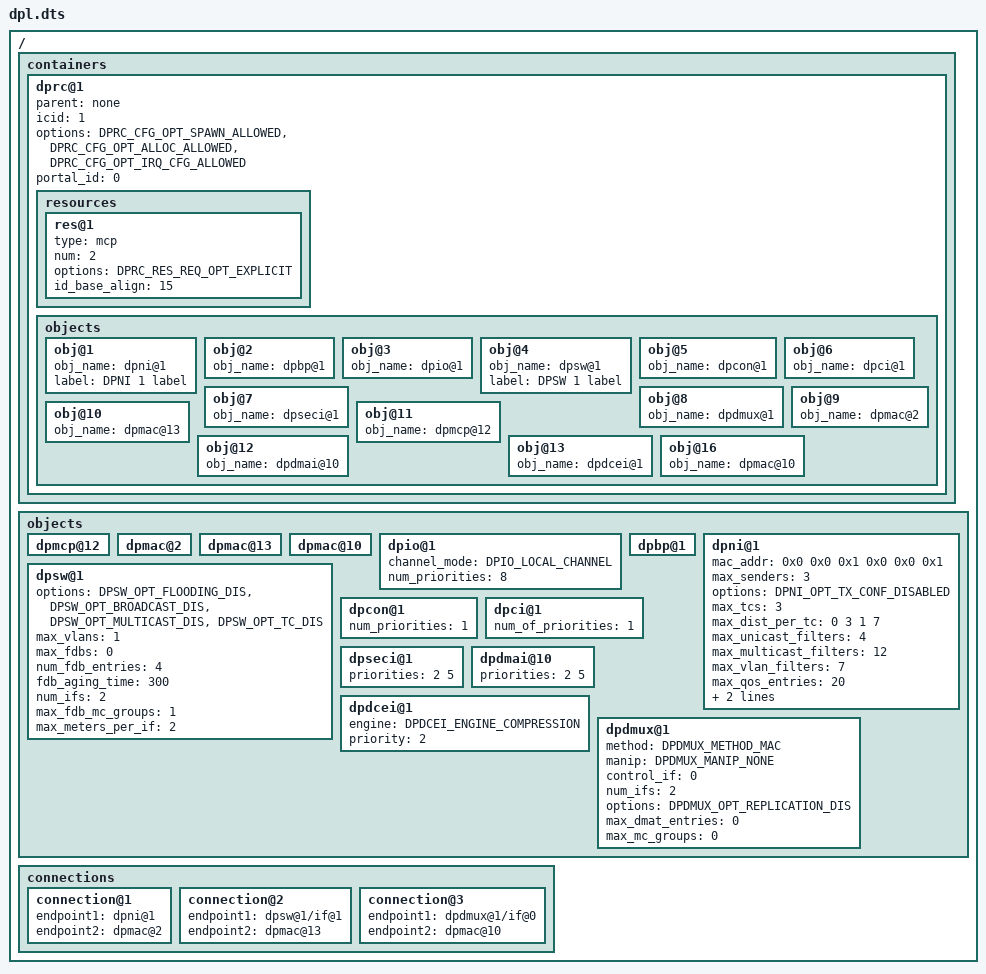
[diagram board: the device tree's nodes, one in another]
/dts-v1/;
/ {	
	containers {
		dprc@1 {
			parent = "none"; 
			icid = <1>;
			options = "DPRC_CFG_OPT_SPAWN_ALLOWED" , "DPRC_CFG_OPT_ALLOC_ALLOWED", "DPRC_CFG_OPT_IRQ_CFG_ALLOWED";
			portal_id = <0>;
			resources {
				res@1 {
					type = "mcp";
					num = <2>;
					options = "DPRC_RES_REQ_OPT_EXPLICIT";
					id_base_align = <15>;
				};
			};
			objects {
				obj@1{
					obj_name = "dpni@1";
					label = "DPNI 1 label";
				};
				obj@2{
					obj_name = "dpbp@1";
				};
				obj@3{
					obj_name = "dpio@1";
				};
				obj@4{
					obj_name = "dpsw@1";
					label = "DPSW 1 label";
				};
				obj@5{
					obj_name = "dpcon@1";
				};
				obj@6{
					obj_name = "dpci@1";
				};
				obj@7{
					obj_name = "dpseci@1";
				};
				obj@8{
					obj_name = "dpdmux@1";
				};
				obj@9{
					obj_name = "dpmac@2";
				};
				obj@10{
					obj_name = "dpmac@13";
				};
				obj@11{
					obj_name = "dpmcp@12";
				};
				obj@12{
					obj_name = "dpdmai@10";
				};
				obj@13{
					obj_name = "dpdcei@1";
				};
				obj@16{
					obj_name = "dpmac@10";
				};
			};
		};
	};
	objects {
		dpmcp@12 {
		};
		dpmac@2 {
		};
		dpmac@13 {
		};
		dpmac@10 {
		};
		dpio@1 {
			channel_mode = "DPIO_LOCAL_CHANNEL";
			num_priorities = <8>;
		};
		dpbp@1 {
		};
		dpni@1{
			mac_addr = < 0x0 0x0 0x1 0x0 0x0 0x1 >; 
			max_senders = <3>; /* actually 4 */
		    options = "DPNI_OPT_TX_CONF_DISABLED";
			max_tcs = <3>; /* actually 4 */
			max_dist_per_tc = <0 3 1 7>; /* actually <1 4 2 8> */	
			max_unicast_filters = <4>;
			max_multicast_filters = <12>;
			max_vlan_filters = <7>;
			max_qos_entries = <20>;
			max_policers = <2>;
			max_congestion_ctrl = <3>;
		};
		dpsw@1{
			options = "DPSW_OPT_FLOODING_DIS", "DPSW_OPT_BROADCAST_DIS", "DPSW_OPT_MULTICAST_DIS", "DPSW_OPT_TC_DIS";
			max_vlans = <1>;				
			max_fdbs = <0>;
			num_fdb_entries = <4>;
			fdb_aging_time = <300>;
			num_ifs = <2>;
			max_fdb_mc_groups = <1>;
			max_meters_per_if = <2>;
		};
		dpcon@1{
			num_priorities = <1>;
		};
		dpci@1{
			num_of_priorities = <1>;
		};
		dpseci@1{
			priorities = < 2 5 >;
		};
		dpdmai@10 {
			priorities = < 2 5 >;
		};
		dpdcei@1 {
			engine = "DPDCEI_ENGINE_COMPRESSION";
			priority = <2>;
		};
		dpdmux@1{
			method = "DPDMUX_METHOD_MAC";
			manip = "DPDMUX_MANIP_NONE";
			control_if = <0>;
			num_ifs = <2>;
			options = "DPDMUX_OPT_REPLICATION_DIS";
			max_dmat_entries = <0>;
			max_mc_groups = <0>;
		};
	};
	connections {
		connection@1{
			endpoint1 = "dpni@1";
			endpoint2 = "dpmac@2";
		};
		connection@2{
			endpoint1 = "dpsw@1/if@1";
			endpoint2 = "dpmac@13";
		};
		connection@3{
			endpoint1 = "dpdmux@1/if@0";
			endpoint2 = "dpmac@10";
		};
	};
};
